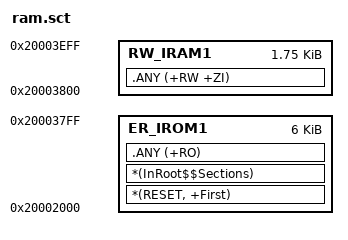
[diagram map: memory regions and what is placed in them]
; *****************************************************************************
;  ram.sct — 把镜像放进内部 RAM，避开原厂固件的变量区
;
;  原厂固件占用: 0x20000000 ~ 0x20001010 (.data/.bss/栈)
;  本镜像放在:   0x20002000 起，留 4KB 安全间隔
;
;  RAM: 0x20000000 ~ 0x20004000 (16KB)
; *****************************************************************************

LR_IROM1 0x20002000 0x00002000  {
  ER_IROM1 0x20002000 0x00001800  {
    *(RESET, +First)
    *(InRoot$$Sections)
    .ANY (+RO)
  }
  RW_IRAM1 0x20003800 0x00000700  {
    .ANY (+RW +ZI)
  }
}
